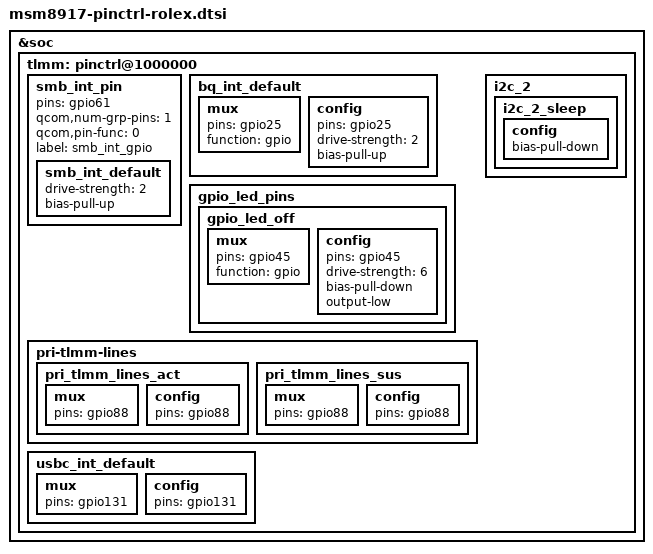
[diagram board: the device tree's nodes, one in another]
/*
 * Copyright (c) 2015-2016, The Linux Foundation. All rights reserved.
 * Copyright (C) 2018 XiaoMi, Inc.
 *
 * This program is free software; you can redistribute it and/or modify
 * it under the terms of the GNU General Public License version 2 and
 * only version 2 as published by the Free Software Foundation.
 *
 * This program is distributed in the hope that it will be useful,
 * but WITHOUT ANY WARRANTY; without even the implied warranty of
 * MERCHANTABILITY or FITNESS FOR A PARTICULAR PURPOSE.  See the
 * GNU General Public License for more details.
 */
&soc {
	tlmm: pinctrl@1000000 {
		smb_int_pin {
			pins = "gpio61";
			qcom,num-grp-pins = <1>;
			qcom,pin-func = <0>;
			label = "smb_int_gpio";
			smb_int_default: smb_int_default {
				drive-strength = <2>;	/*8 MA */
				bias-pull-up;		/* PULL UP*/
			};
		};
		bq_int_default: bq_int_default {
			mux {
				pins = "gpio25";
				function ="gpio";
			};
			config {
				pins = "gpio25";
				drive-strength = <2>; /* 2 MA */
				bias-pull-up;
				/* PULL UP*/
				};
		};
		gpio_led_pins {
			gpio_led_off: gpio_led_off {
				mux {
					pins = "gpio45";
					function = "gpio";
			 	};
				config {
					pins = "gpio45";
					drive-strength = <6>;
					bias-pull-down;
					output-low;
				};
			};
		};

		pri-tlmm-lines {
			pri_tlmm_lines_act: pri_tlmm_lines_act {
				mux {
					pins = "gpio88";
				};

				config {
					pins = "gpio88";
				};
			};

			pri_tlmm_lines_sus: pri_tlmm_lines_sus {
				mux {
					pins = "gpio88";
				};

				config {
					pins = "gpio88";
				};
			};
		};

		i2c_2 {
			i2c_2_sleep: i2c_2_sleep {
				config {
					/delete-property/ bias-disable;
					bias-pull-down;
				};
			};
		};

		usbc_int_default: usbc_int_default {
			mux {
				pins = "gpio131";
			};

			config {
				pins = "gpio131";
			};
		};
	};
};
